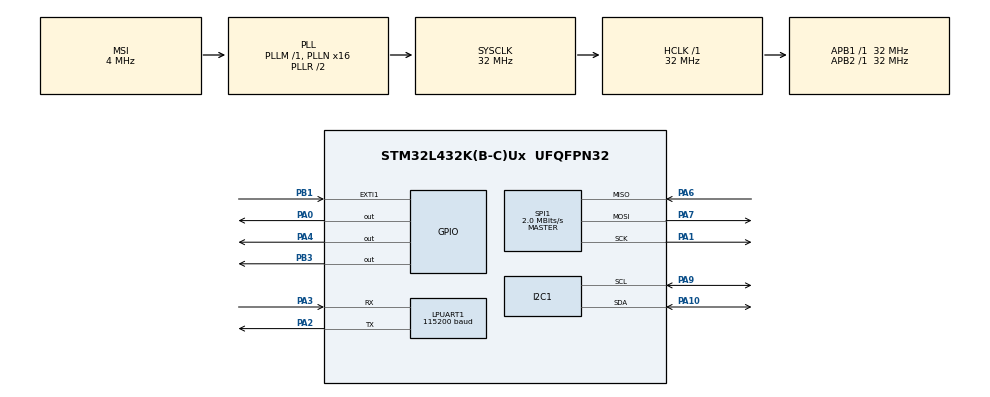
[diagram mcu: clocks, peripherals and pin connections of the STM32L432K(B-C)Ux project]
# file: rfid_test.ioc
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I2C1.Timing=0x00B07CB4
LPUART1.BaudRate=115200
LPUART1.WordLength=UART_WORDLENGTH_8B
Mcu.Family=STM32L4
Mcu.Name=STM32L432K(B-C)Ux
Mcu.Package=UFQFPN32
NVIC.EXTI1_IRQn=true\:0\:0\:false\:false\:true\:true\:true\:true
NVIC.PriorityGroup=NVIC_PRIORITYGROUP_4
NVIC.TIM6_DAC_IRQn=true\:0\:0\:false\:false\:true\:true\:true\:true
NVIC.TIM7_IRQn=true\:0\:0\:false\:false\:true\:true\:true\:true
PA0.Signal=GPIO_Output
PA1.Mode=Full_Duplex_Master
PA1.Signal=SPI1_SCK
PA10.Mode=I2C
PA10.Signal=I2C1_SDA
PA2.Mode=Asynchronous
PA2.Signal=LPUART1_TX
PA3.Mode=Asynchronous
PA3.Signal=LPUART1_RX
PA4.Signal=GPIO_Output
PA6.Mode=Full_Duplex_Master
PA6.Signal=SPI1_MISO
PA7.Mode=Full_Duplex_Master
PA7.Signal=SPI1_MOSI
PA9.Mode=I2C
PA9.Signal=I2C1_SCL
PB1.Signal=GPXTI1
PB3\ (JTDO-TRACESWO).Signal=GPIO_Output
ProjectManager.HeapSize=0x200
ProjectManager.StackSize=0x400
ProjectManager.TargetToolchain=STM32CubeIDE
RCC.AHBFreq_Value=32000000
RCC.APB1Freq_Value=32000000
RCC.APB1TimFreq_Value=32000000
RCC.APB2Freq_Value=32000000
RCC.APB2TimFreq_Value=32000000
RCC.CortexFreq_Value=32000000
RCC.HCLKFreq_Value=32000000
RCC.HSE_VALUE=8000000
RCC.HSI16_VALUE=16000000
RCC.HSI48_VALUE=48000000
RCC.HSI_VALUE=16000000
RCC.LSE_VALUE=32768
RCC.MSI_VALUE=4000000
RCC.PLLMUL=RCC_PLLMUL_4
RCC.PLLN=16
RCC.SYSCLKFreq_VALUE=32000000
RCC.SYSCLKSource=RCC_SYSCLKSOURCE_PLLCLK
RCC.VCOOutputFreq_Value=64000000
SPI1.BaudRatePrescaler=SPI_BAUDRATEPRESCALER_16
SPI1.CalculateBaudRate=2.0 MBits/s
SPI1.DataSize=SPI_DATASIZE_8BIT
SPI1.Direction=SPI_DIRECTION_2LINES
SPI1.Mode=SPI_MODE_MASTER
SPI1.VirtualType=VM_MASTER
TIM6.Period=9999
TIM6.Prescaler=7999
TIM7.Period=999
TIM7.Prescaler=39999
VP_TIM6_VS_ClockSourceINT.Mode=Enable_Timer
VP_TIM7_VS_ClockSourceINT.Mode=Enable_Timer
board=NUCLEO-L432KC

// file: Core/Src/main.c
/* USER CODE BEGIN Header */
/**
  ******************************************************************************
  * @file           : main.c
  * @brief          : Main program body
  ******************************************************************************
  * @attention
  *
  * Copyright (c) 2024 STMicroelectronics.
  * All rights reserved.
  *
  * This software is licensed under terms that can be found in the LICENSE file
  * in the root directory of this software component.
  * If no LICENSE file comes with this software, it is provided AS-IS.
  *
  ******************************************************************************
  */
/* USER CODE END Header */
#include "main.h"

I2C_HandleTypeDef hi2c1;

UART_HandleTypeDef hlpuart1;

SPI_HandleTypeDef hspi1;

TIM_HandleTypeDef htim6;
TIM_HandleTypeDef htim7;

void SystemClock_Config(void);
static void MX_GPIO_Init(void);
static void MX_LPUART1_UART_Init(void);
static void MX_TIM6_Init(void);
static void MX_TIM7_Init(void);
static void MX_SPI1_Init(void);
static void MX_I2C1_Init(void);

/* USER CODE BEGIN 0 */
void Init();
/* USER CODE END 0 */

int main(void)
{

  /* MCU Configuration--------------------------------------------------------*/

  /* Reset of all peripherals, Initializes the Flash interface and the Systick. */
  HAL_Init();

  /* Configure the system clock */
  SystemClock_Config();

  /* Initialize all configured peripherals */
  MX_GPIO_Init();
  MX_LPUART1_UART_Init();
  MX_TIM6_Init();
  MX_TIM7_Init();
  MX_SPI1_Init();
  MX_I2C1_Init();
  /* USER CODE BEGIN 2 */
  Init();
  /* USER CODE END 2 */

  /* Infinite loop */
  /* USER CODE BEGIN WHILE */
  while (1)
  {
	  HAL_Delay(1000);
    /* USER CODE END WHILE */

  }
}

void SystemClock_Config(void)
{
  RCC_OscInitTypeDef RCC_OscInitStruct = {0};
  RCC_ClkInitTypeDef RCC_ClkInitStruct = {0};

  /** Configure the main internal regulator output voltage
  */
  if (HAL_PWREx_ControlVoltageScaling(PWR_REGULATOR_VOLTAGE_SCALE1) != HAL_OK)
  {
    Error_Handler();
  }

  /** Initializes the RCC Oscillators according to the specified parameters
  * in the RCC_OscInitTypeDef structure.
  */
  RCC_OscInitStruct.OscillatorType = RCC_OSCILLATORTYPE_MSI;
  RCC_OscInitStruct.MSIState = RCC_MSI_ON;
  RCC_OscInitStruct.MSICalibrationValue = 0;
  RCC_OscInitStruct.MSIClockRange = RCC_MSIRANGE_6;
  RCC_OscInitStruct.PLL.PLLState = RCC_PLL_ON;
  RCC_OscInitStruct.PLL.PLLSource = RCC_PLLSOURCE_MSI;
  RCC_OscInitStruct.PLL.PLLM = 1;
  RCC_OscInitStruct.PLL.PLLN = 16;
  RCC_OscInitStruct.PLL.PLLP = RCC_PLLP_DIV7;
  RCC_OscInitStruct.PLL.PLLQ = RCC_PLLQ_DIV2;
  RCC_OscInitStruct.PLL.PLLR = RCC_PLLR_DIV2;
  if (HAL_RCC_OscConfig(&RCC_OscInitStruct) != HAL_OK)
  {
    Error_Handler();
  }

  /** Initializes the CPU, AHB and APB buses clocks
  */
  RCC_ClkInitStruct.ClockType = RCC_CLOCKTYPE_HCLK|RCC_CLOCKTYPE_SYSCLK
                              |RCC_CLOCKTYPE_PCLK1|RCC_CLOCKTYPE_PCLK2;
  RCC_ClkInitStruct.SYSCLKSource = RCC_SYSCLKSOURCE_PLLCLK;
  RCC_ClkInitStruct.AHBCLKDivider = RCC_SYSCLK_DIV1;
  RCC_ClkInitStruct.APB1CLKDivider = RCC_HCLK_DIV1;
  RCC_ClkInitStruct.APB2CLKDivider = RCC_HCLK_DIV1;

  if (HAL_RCC_ClockConfig(&RCC_ClkInitStruct, FLASH_LATENCY_1) != HAL_OK)
  {
    Error_Handler();
  }
}

static void MX_I2C1_Init(void)
{

  hi2c1.Instance = I2C1;
  hi2c1.Init.Timing = 0x00B07CB4;
  hi2c1.Init.OwnAddress1 = 0;
  hi2c1.Init.AddressingMode = I2C_ADDRESSINGMODE_7BIT;
  hi2c1.Init.DualAddressMode = I2C_DUALADDRESS_DISABLE;
  hi2c1.Init.OwnAddress2 = 0;
  hi2c1.Init.OwnAddress2Masks = I2C_OA2_NOMASK;
  hi2c1.Init.GeneralCallMode = I2C_GENERALCALL_DISABLE;
  hi2c1.Init.NoStretchMode = I2C_NOSTRETCH_DISABLE;
  if (HAL_I2C_Init(&hi2c1) != HAL_OK)
  {
    Error_Handler();
  }

  /** Configure Analogue filter
  */
  if (HAL_I2CEx_ConfigAnalogFilter(&hi2c1, I2C_ANALOGFILTER_ENABLE) != HAL_OK)
  {
    Error_Handler();
  }

  /** Configure Digital filter
  */
  if (HAL_I2CEx_ConfigDigitalFilter(&hi2c1, 0) != HAL_OK)
  {
    Error_Handler();
  }

}

static void MX_LPUART1_UART_Init(void)
{

  hlpuart1.Instance = LPUART1;
  hlpuart1.Init.BaudRate = 115200;
  hlpuart1.Init.WordLength = UART_WORDLENGTH_8B;
  hlpuart1.Init.StopBits = UART_STOPBITS_1;
  hlpuart1.Init.Parity = UART_PARITY_NONE;
  hlpuart1.Init.Mode = UART_MODE_TX_RX;
  hlpuart1.Init.HwFlowCtl = UART_HWCONTROL_NONE;
  hlpuart1.Init.OneBitSampling = UART_ONE_BIT_SAMPLE_DISABLE;
  hlpuart1.AdvancedInit.AdvFeatureInit = UART_ADVFEATURE_NO_INIT;
  if (HAL_UART_Init(&hlpuart1) != HAL_OK)
  {
    Error_Handler();
  }

}

static void MX_SPI1_Init(void)
{

  /* SPI1 parameter configuration*/
  hspi1.Instance = SPI1;
  hspi1.Init.Mode = SPI_MODE_MASTER;
  hspi1.Init.Direction = SPI_DIRECTION_2LINES;
  hspi1.Init.DataSize = SPI_DATASIZE_8BIT;
  hspi1.Init.CLKPolarity = SPI_POLARITY_LOW;
  hspi1.Init.CLKPhase = SPI_PHASE_1EDGE;
  hspi1.Init.NSS = SPI_NSS_SOFT;
  hspi1.Init.BaudRatePrescaler = SPI_BAUDRATEPRESCALER_16;
  hspi1.Init.FirstBit = SPI_FIRSTBIT_MSB;
  hspi1.Init.TIMode = SPI_TIMODE_DISABLE;
  hspi1.Init.CRCCalculation = SPI_CRCCALCULATION_DISABLE;
  hspi1.Init.CRCPolynomial = 7;
  hspi1.Init.CRCLength = SPI_CRC_LENGTH_DATASIZE;
  hspi1.Init.NSSPMode = SPI_NSS_PULSE_ENABLE;
  if (HAL_SPI_Init(&hspi1) != HAL_OK)
  {
    Error_Handler();
  }

}

static void MX_TIM6_Init(void)
{

  TIM_MasterConfigTypeDef sMasterConfig = {0};

  htim6.Instance = TIM6;
  htim6.Init.Prescaler = 7999;
  htim6.Init.CounterMode = TIM_COUNTERMODE_UP;
  htim6.Init.Period = 9999;
  htim6.Init.AutoReloadPreload = TIM_AUTORELOAD_PRELOAD_DISABLE;
  if (HAL_TIM_Base_Init(&htim6) != HAL_OK)
  {
    Error_Handler();
  }
  sMasterConfig.MasterOutputTrigger = TIM_TRGO_RESET;
  sMasterConfig.MasterSlaveMode = TIM_MASTERSLAVEMODE_DISABLE;
  if (HAL_TIMEx_MasterConfigSynchronization(&htim6, &sMasterConfig) != HAL_OK)
  {
    Error_Handler();
  }

}

static void MX_TIM7_Init(void)
{

  TIM_MasterConfigTypeDef sMasterConfig = {0};

  htim7.Instance = TIM7;
  htim7.Init.Prescaler = 39999;
  htim7.Init.CounterMode = TIM_COUNTERMODE_UP;
  htim7.Init.Period = 999;
  htim7.Init.AutoReloadPreload = TIM_AUTORELOAD_PRELOAD_DISABLE;
  if (HAL_TIM_Base_Init(&htim7) != HAL_OK)
  {
    Error_Handler();
  }
  sMasterConfig.MasterOutputTrigger = TIM_TRGO_RESET;
  sMasterConfig.MasterSlaveMode = TIM_MASTERSLAVEMODE_DISABLE;
  if (HAL_TIMEx_MasterConfigSynchronization(&htim7, &sMasterConfig) != HAL_OK)
  {
    Error_Handler();
  }

}

static void MX_GPIO_Init(void)
{
  GPIO_InitTypeDef GPIO_InitStruct = {0};

  /* GPIO Ports Clock Enable */
  __HAL_RCC_GPIOA_CLK_ENABLE();
  __HAL_RCC_GPIOB_CLK_ENABLE();

  /*Configure GPIO pin Output Level */
  HAL_GPIO_WritePin(GPIOA, GPIO_PIN_0|GPIO_PIN_4, GPIO_PIN_RESET);

  /*Configure GPIO pin Output Level */
  HAL_GPIO_WritePin(GPIOB, GPIO_PIN_3, GPIO_PIN_RESET);

  /*Configure GPIO pins : PA0 PA4 */
  GPIO_InitStruct.Pin = GPIO_PIN_0|GPIO_PIN_4;
  GPIO_InitStruct.Mode = GPIO_MODE_OUTPUT_PP;
  GPIO_InitStruct.Pull = GPIO_NOPULL;
  GPIO_InitStruct.Speed = GPIO_SPEED_FREQ_LOW;
  HAL_GPIO_Init(GPIOA, &GPIO_InitStruct);

  /*Configure GPIO pin : PB1 */
  GPIO_InitStruct.Pin = GPIO_PIN_1;
  GPIO_InitStruct.Mode = GPIO_MODE_IT_RISING;
  GPIO_InitStruct.Pull = GPIO_NOPULL;
  HAL_GPIO_Init(GPIOB, &GPIO_InitStruct);

  /*Configure GPIO pin : PB3 */
  GPIO_InitStruct.Pin = GPIO_PIN_3;
  GPIO_InitStruct.Mode = GPIO_MODE_OUTPUT_PP;
  GPIO_InitStruct.Pull = GPIO_NOPULL;
  GPIO_InitStruct.Speed = GPIO_SPEED_FREQ_LOW;
  HAL_GPIO_Init(GPIOB, &GPIO_InitStruct);

  /* EXTI interrupt init*/
  HAL_NVIC_SetPriority(EXTI1_IRQn, 0, 0);
  HAL_NVIC_EnableIRQ(EXTI1_IRQn);

}

/* USER CODE BEGIN 4 */

#ifdef __GNUC__
#define PUTCHAR_PROTOTYPE int __io_putchar(int ch)
#else
#define PUTCHAR_PROTOTYPE int fputc(int ch, FILE *f)
#endif /* __GNUC__ */
PUTCHAR_PROTOTYPE
{
  HAL_UART_Transmit(&hlpuart1, (uint8_t *)&ch, 1, 0xFFFF);
  return ch;
}

/* USER CODE END 4 */

void Error_Handler(void)
{
  __disable_irq();
  while (1)
  {
  }
}
